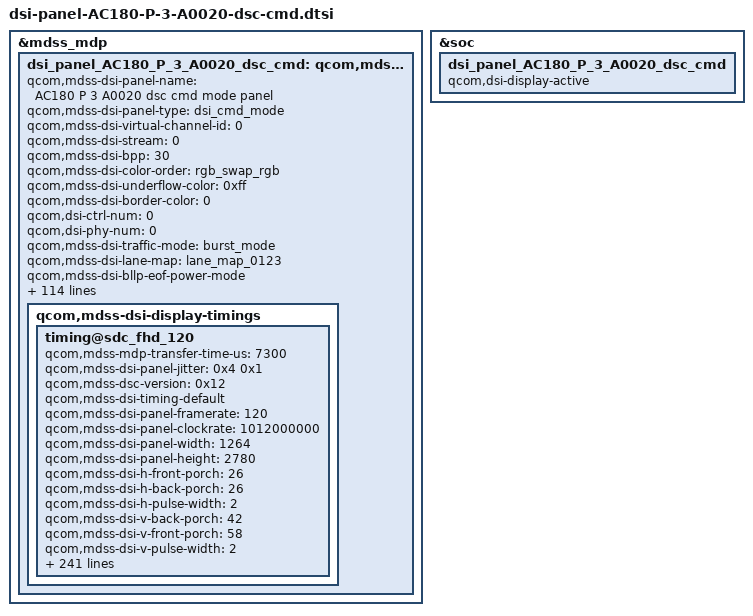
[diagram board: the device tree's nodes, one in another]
&mdss_mdp {
	dsi_panel_AC180_P_3_A0020_dsc_cmd: qcom,mdss_dsi_panel_AC180_P_3_A0020_dsc_cmd {
		qcom,mdss-dsi-panel-name = "AC180 P 3 A0020 dsc cmd mode panel";
		qcom,mdss-dsi-panel-type = "dsi_cmd_mode";
		qcom,mdss-dsi-virtual-channel-id = <0>;
		qcom,mdss-dsi-stream = <0>;
		qcom,mdss-dsi-bpp = <30>;
		qcom,mdss-dsi-color-order = "rgb_swap_rgb";
		qcom,mdss-dsi-underflow-color = <0xff>;
		qcom,mdss-dsi-border-color = <0>;
		qcom,dsi-ctrl-num = <0>;
		qcom,dsi-phy-num = <0>;
		qcom,mdss-dsi-traffic-mode = "burst_mode";
		qcom,mdss-dsi-lane-map = "lane_map_0123";
		qcom,mdss-dsi-bllp-eof-power-mode;
		qcom,mdss-dsi-bllp-power-mode;
		qcom,mdss-dsi-lane-0-state;
		qcom,mdss-dsi-lane-1-state;
		qcom,mdss-dsi-lane-2-state;
		qcom,mdss-dsi-lane-3-state;
		qcom,mdss-dsi-dma-trigger = "trigger_sw";
		qcom,mdss-dsi-dma-schedule-line = <1>;
		qcom,mdss-dsi-dma-schedule-window = <10>;
		qcom,mdss-dsi-mdp-trigger = "none";
		qcom,mdss-dsi-reset-sequence = <1 2>, <0 5>, <1 25>;
		qcom,mdss-dsi-te-pin-select = <1>;
		qcom,mdss-dsi-te-dcs-command = <1>;
		qcom,mdss-pan-physical-width-dimension = <71>;
		qcom,mdss-pan-physical-height-dimension = <157>;
		qcom,mdss-dsi-init-delay-us = <1000>;
		qcom,mdss-dsi-te-check-enable;
		qcom,mdss-dsi-te-using-te-pin;
		qcom,mdss-dsi-lp11-init;
		qcom,mdss-dsi-wr-mem-start = <0x2c>;
		qcom,mdss-dsi-wr-mem-continue = <0x3c>;
		qcom,mdss-dsi-panel-jitter = <0x4 0x1>;
		qcom,mdss-bl-high2bit;
  		/* HDR Setting */
		qcom,mdss-dsi-panel-hdr-enabled;
		qcom,mdss-dsi-panel-hdr-color-primaries = <15635 16450 34000 16000 13250 34500 7500 3000>;
		//update for [MPC15]android.mediapc.cts.PerformanceClassTest#testDisplayHdr pass
		//qcom,mdss-dsi-panel-peak-brightness = <5400000>;
		qcom,mdss-dsi-panel-peak-brightness = <20000000>;
		qcom,mdss-dsi-panel-average-brightness = <2000000>;
		qcom,mdss-dsi-panel-blackness-level = <4000>;


		qcom,dynamic-mode-switch-enabled;
		qcom,dynamic-mode-switch-type = "dynamic-resolution-switch-immediate";
		qcom,mdss-dsi-display-timings {
			timing@sdc_fhd_120 {
				#include "dsi-panel-AC180-P-3-A0020-common.dtsi"
				qcom,mdss-mdp-transfer-time-us = <7300>;
				qcom,mdss-dsi-panel-jitter = <0x4 0x1>;
				qcom,mdss-dsc-version = <0x12>;
				qcom,mdss-dsi-timing-default;
				qcom,mdss-dsi-panel-framerate = <120>;
				qcom,mdss-dsi-panel-clockrate = <1012000000>;
				qcom,mdss-dsi-panel-width = <1264>;
				qcom,mdss-dsi-panel-height = <2780>;

				qcom,mdss-dsi-h-front-porch = <26>;
				qcom,mdss-dsi-h-back-porch = <26>;
				qcom,mdss-dsi-h-pulse-width = <2>;
				qcom,mdss-dsi-v-back-porch = <42>;
				qcom,mdss-dsi-v-front-porch = <58>;
				qcom,mdss-dsi-v-pulse-width = <2>;
				qcom,mdss-dsi-h-sync-pulse = <0>;

				oplus,ofp-need-to-sync-data-in-aod-unlocking;
				oplus,ofp-aod-off-insert-black-frame = <1>;
				oplus,ofp-aod-off-black-frame-total-time = <42>;
				oplus,ofp-need-to-separate-backlight;
				oplus,ofp-backlight-on-period = <1>;

				qcom,mdss-dsi-timing-switch-command = [
					39 00 00 40 00 00 04 FF 5A A5 00
					15 00 00 40 00 00 02 60 00
					/* recover to narrow TE */
					39 00 00 40 00 00 04 FF 5A A5 02
					39 00 00 40 00 00 09 B0 00 80 00 10 00 00 00 00
					39 00 00 40 00 00 04 FF 5A A5 2D
					39 00 00 40 00 00 03 83 00 00
					15 00 00 40 00 00 02 F2 00
					39 00 00 00 00 00 04 FF 5A A5 00
				];
				qcom,mdss-dsi-on-command = [
					39 00 00 40 00 00 04 FF 5A A5 20
					15 00 00 40 00 00 02 BF 06
					39 00 00 40 00 00 04 FF 5A A5 00
					39 00 00 40 00 00 05 94 00 D0 00 00
					39 00 00 40 00 00 04 FF 5A A5 1F
					39 00 00 40 00 00 03 82 00 20
					15 00 00 40 00 00 02 87 09
					15 00 00 40 00 00 02 88 34
					39 00 00 40 00 00 05 89 C1 80 C0 01
					39 00 00 40 00 00 03 8A 8C 14
					39 00 00 40 00 00 05 8C 80 07 00 40
					15 00 00 40 00 00 02 8E 10
					39 00 00 40 00 00 05 96 15 35 55 00
					39 00 00 40 00 00 06 97 11 33 22 01 09
					39 00 00 40 00 00 19 83 00 0B 0A 0C 02 FF FF FF 0C 02 FF FF 00 FF 00 0B 00 FF FF FF FF FF FF FF
					39 00 00 40 00 00 19 8F 03 2D 8C 19 07 00 00 00 19 07 00 00 00 00 02 2D 02 00 00 00 00 00 00 00
					39 00 00 40 00 00 04 85 00 0B 0A
					39 00 00 40 00 00 04 91 03 2D 72
					39 00 00 40 00 00 04 FF 5A A5 29
					39 00 00 40 00 00 09 82 90 90 6C 28 14 14 14 14
					39 00 00 40 00 00 09 83 14 14 14 14 14 14 14 14
					39 00 00 40 00 00 09 84 14 14 14 14 14 14 14 14
					39 00 00 40 00 00 07 85 14 14 14 14 14 14
					39 00 00 40 00 00 04 FF 5A A5 00

					39 00 00 40 00 00 04 FF 5A A5 08
					15 00 00 40 00 00 02 C8 62
					39 00 00 40 00 00 04 FF 5A A5 07
					15 00 00 40 00 00 02 8A 01
					39 00 00 40 00 00 03 8B 21 E0
					39 00 00 40 00 00 64 81 00 00 00 00 00 12 00 00 AB 30 80 0A DC 04 F0 00 14 02 78 02 78 02 00 02 57 00 20 01 F8 00 08 00 0D 05 7A 04 4F 18 00 10 E0 07 10 20 00 06 0F 0F 33 0E 1C 2A 38 46 54 62 69 70 77 79 7B 7D 7E 02 02 22 00 2A 40 2A BE 3A FC 3A FA 3A F8 3B 38 3B 78 3B B6 4B B6 4B F4 4B F4 6C 34 84 74 74 00 00 00 00 00

					39 00 00 40 00 00 04 FF 5A A5 21
					15 00 00 40 00 00 02 A4 18
					39 00 00 40 00 00 04 FF 5A A5 00
					15 00 00 40 00 00 02 5E 01
					15 00 00 40 00 00 02 60 00
					15 00 00 40 00 00 02 61 07
					15 00 00 40 00 00 02 35 00
					15 00 00 40 00 00 02 53 20
					/* decreasing step */
					39 00 00 40 00 00 04 FF 5A A5 2D
					15 00 00 40 00 00 02 97 03
					15 00 00 40 00 00 02 B1 03
					39 00 00 40 00 00 03 98 03 00
					39 00 00 40 00 00 03 99 05 00
					39 00 00 40 00 00 03 9A 0B 00
					39 00 00 40 00 00 03 9B 17 00
					39 00 00 40 00 00 03 A0 00 00
					39 00 00 40 00 00 03 A1 01 02
					15 00 00 40 00 00 03 B2 02 00
					15 00 00 40 00 00 03 B3 04 00
					15 00 00 40 00 00 03 B4 08 00
					15 00 00 40 00 00 03 B5 11 00
					39 00 00 40 00 00 03 BA 00 00
					39 00 00 40 00 00 03 BB 01 02
					/* Narrow TE */
					39 00 00 40 00 00 04 FF 5A A5 02
					39 00 00 40 00 00 09 B0 00 80 00 10 00 00 00 00
					// switch 120HZ
					39 00 00 40 00 00 04 FF 5A A5 00
					15 00 00 40 00 00 02 60 00
					39 00 00 40 00 00 04 FF 5A A5 2D
					39 00 00 40 00 00 03 83 00 00
					15 00 00 40 00 00 02 F2 00
					39 00 00 00 02 00 04 FF 5A A5 00
					//screen on code
					15 00 00 00 78 00 02 11 00
					15 00 00 00 14 00 02 29 00
				];
				qcom,mdss-dsi-off-command=[
					05 00 00 00 14 00 01 28
					05 00 00 00 78 00 01 10
				];
				qcom,mdss-dsi-hbm-off-command = [
					39 00 00 00 00 00 03 51 0D BB
				];
				qcom,mdss-dsi-hbm-on-command = [
					39 00 00 00 00 00 03 51 0E E0
				];
				qcom,mdss-dsi-change-voltage-before-bl-0-command = [
					//Vinit2 ELVSS
					39 00 00 40 00 00 04 FF 5A A5 1F
					15 00 00 40 00 00 02 88 00
					39 00 00 40 00 00 04 FF 5A A5 4E
					15 00 00 40 00 00 02 8C 10
					39 00 00 40 00 00 08 95 00 00 00 00 FF 03 30
					39 00 00 00 00 00 04 FF 5A A5 00
				];
				qcom,mdss-dsi-lhbm-pressed-icon-on-command = [
					39 00 00 40 00 00 04 FF 5A A5 00
					39 00 00 40 00 00 02 96 09
					39 00 00 40 00 00 02 97 D9
					39 00 00 40 00 00 02 98 02
					39 00 00 40 00 00 02 99 78
					39 00 00 00 00 00 02 6E 03
				];
				qcom,mdss-dsi-lhbm-pressed-icon-off-command = [
					39 00 00 40 00 00 04 FF 5A A5 00
					39 00 00 00 00 00 02 6E 00
				];
				qcom,mdss-dsi-lp1-command = [
					39 00 00 40 00 00 04 FF 5A A5 02
					39 00 00 40 00 00 03 88 08 00
					39 00 00 40 00 00 04 FF 5A A5 4F
					15 00 00 40 00 00 02 88 78
					39 00 00 40 00 00 04 FF 5A A5 00
					15 00 00 40 00 00 02 60 00
					39 00 00 40 00 00 04 FF 5A A5 53
					39 00 00 40 00 00 03 85 CC E1
					39 00 00 40 00 00 04 FF 5A A5 01
					39 00 00 40 00 00 06 83 00 00 40 04 00
					15 00 00 40 00 00 02 FE 0B
					39 00 00 40 00 00 04 FF 5A A5 0B
					15 00 00 40 00 00 02 88 00
					15 00 00 40 00 00 02 A7 00
					39 00 00 40 00 00 04 FF 5A A5 51
					39 00 00 40 00 00 06 C2 46 46 46 46 00
					15 00 00 40 00 00 02 FE 00
					15 00 00 40 00 00 02 00 00
					39 00 00 40 00 00 04 FF 5A A5 00
					15 00 00 40 00 00 02 39 00
					39 00 00 40 00 00 04 FF 5A A5 4F
					15 00 00 40 00 00 02 8B 78
					/* AOD lv switch */
					39 00 00 40 00 00 04 FF 5A A5 00
					39 00 00 00 00 00 05 51 00 00 0D BB
				];
				qcom,mdss-dsi-nolp-command = [
					39 00 00 40 00 00 04 FF 5A A5 02
					39 00 00 40 00 00 03 88 C0 00
					39 00 00 40 00 00 04 FF 5A A5 00
					15 00 00 40 00 00 02 38 00
					39 00 00 00 00 00 05 51 00 00 00 00
				];
				qcom,mdss-dsi-aod-off-pwm-mode2-command = [
					39 00 00 40 00 00 04 FF 5A A5 4F
					15 00 00 40 00 00 02 88 78
					39 00 00 40 00 00 04 FF 5A A5 01
					39 00 00 40 00 00 03 80 0C 0C
					39 00 00 40 00 00 04 FF 5A A5 4F
					15 00 00 40 00 00 02 8A 78
					39 00 00 40 00 00 04 FF 5A A5 00
					15 00 00 40 00 00 02 60 01
					39 00 00 40 00 00 04 FF 5A A5 53
					39 00 00 40 00 00 03 85 CC E3
					39 00 00 40 00 00 04 FF 5A A5 01
					39 00 00 40 00 00 06 83 00 00 40 04 00
					15 00 00 40 00 00 02 FE 07
					39 00 00 40 00 00 04 FF 5A A5 0B
					15 00 00 40 00 00 02 88 46
					15 00 00 40 00 00 02 A7 3A
					39 00 00 40 00 00 04 FF 5A A5 51
					39 00 00 40 00 00 06 C2 46 28 28 28 00
					15 00 00 40 00 00 02 FE 00
					15 00 00 40 00 00 02 00 00
					39 00 00 40 00 00 04 FF 5A A5 01
					39 00 00 40 00 00 03 80 0C 00
					39 00 00 40 00 00 04 FF 5A A5 02
					39 00 00 40 00 00 03 88 C0 00
					39 00 00 40 00 00 04 FF 5A A5 00
					15 00 00 40 00 00 02 38 00
					39 00 00 40 00 00 04 FF 5A A5 4F
					15 00 00 40 00 00 02 8B 78
					39 00 00 40 00 00 04 FF 5A A5 00
					39 00 00 00 00 00 03 51 00 00
				];
				qcom,mdss-dsi-aod-off-compensation-command = [
					39 00 00 40 00 00 04 FF 5A A5 02
					39 00 00 40 00 00 03 88 C0 00
					39 00 00 40 00 00 04 FF 5A A5 4F
					15 00 00 40 00 00 02 80 01
					15 00 00 40 00 00 02 81 04
					15 00 00 40 00 00 02 88 78
					39 00 00 40 00 00 04 FF 5A A5 1F
					39 00 00 40 00 00 06 89 43 00 0B F0 BB
					39 00 00 40 00 00 03 82 08 08
					39 00 00 40 00 00 06 85 7F 7F 7F 7F 73
					39 00 00 40 00 00 04 FF 5A A5 00
					15 00 00 40 00 00 02 4D 01
					39 00 00 40 00 00 04 FF 5A A5 13
					15 00 00 40 00 00 02 CB 00
					39 00 00 40 00 00 04 FF 5A A5 4F
					15 00 00 40 00 00 02 8A 78
					39 00 00 40 00 00 04 FF 5A A5 1F
					39 00 00 40 00 00 06 89 43 00 04 F0 55
					39 00 00 40 00 00 03 82 00 80
					39 00 00 40 00 00 06 85 5F 7F 00 00 00
					39 00 00 40 00 00 04 FF 5A A5 00
					15 00 00 40 00 00 02 38 00
					39 00 00 40 00 00 04 FF 5A A5 00
					15 00 00 40 00 00 02 4D 00
					39 00 00 40 00 00 04 FF 5A A5 13
					15 00 00 40 00 00 02 CB 01
					39 00 00 40 00 00 04 FF 5A A5 00
					15 00 00 40 00 00 02 00 00
					39 00 00 40 00 00 04 FF 5A A5 4F
					15 00 00 00 00 00 02 8B 78
				];
				qcom,mdss-dsi-aod-off-compensation-onepulse-command = [
					39 00 00 40 00 00 04 FF 5A A5 02
					39 00 00 40 00 00 03 88 C0 00
					39 00 00 40 00 00 04 FF 5A A5 4F
					15 00 00 40 00 00 02 80 01
					15 00 00 40 00 00 02 81 04
					15 00 00 40 00 00 02 88 78
					39 00 00 40 00 00 04 FF 5A A5 01
					39 00 00 40 00 00 03 80 0C 0C
					39 00 00 40 00 00 04 FF 5A A5 1F
					39 00 00 40 00 00 06 89 43 00 0B F0 BB
					39 00 00 40 00 00 03 82 08 08
					39 00 00 40 00 00 06 85 7F 7F 7F 7F 73
					39 00 00 40 00 00 04 FF 5A A5 00
					15 00 00 40 00 00 02 4D 01
					39 00 00 40 00 00 04 FF 5A A5 13
					15 00 00 40 00 00 02 CB 00
					39 00 00 40 00 00 04 FF 5A A5 4F
					15 00 00 40 00 00 02 8A 78
					39 00 00 40 00 00 04 FF 5A A5 1F
					39 00 00 40 00 00 06 89 43 00 04 F0 55
					39 00 00 40 00 00 03 82 00 80
					39 00 00 40 00 00 06 85 5F 7F 00 00 00
					39 00 00 40 00 00 04 FF 5A A5 00
					15 00 00 40 00 00 02 60 01
					39 00 00 40 00 00 04 FF 5A A5 53
					39 00 00 40 00 00 03 85 CC E3
					39 00 00 40 00 00 04 FF 5A A5 01
					39 00 00 40 00 00 06 83 00 00 40 04 00
					15 00 00 40 00 00 02 FE 07
					39 00 00 40 00 00 04 FF 5A A5 0B
					15 00 00 40 00 00 02 88 46
					15 00 00 40 00 00 02 A7 3A
					39 00 00 40 00 00 04 FF 5A A5 51
					39 00 00 40 00 00 06 C2 46 28 28 28 00
					15 00 00 40 00 00 02 FE 00
					15 00 00 40 00 00 02 00 00
					39 00 00 40 00 00 04 FF 5A A5 01
					39 00 00 40 00 00 03 80 0C 00
					39 00 00 40 00 00 04 FF 5A A5 00
					15 00 00 40 00 00 02 38 00
					39 00 00 40 00 00 04 FF 5A A5 00
					15 00 00 40 00 00 02 4D 00
					39 00 00 40 00 00 04 FF 5A A5 13
					15 00 00 40 00 00 02 CB 01
					39 00 00 40 00 00 04 FF 5A A5 00
					15 00 00 40 00 00 02 00 00
					39 00 00 40 00 00 04 FF 5A A5 4F
					15 00 00 00 00 00 02 8B 78
				];
				qcom,mdss-dsi-aod-high-mode-command = [
					39 00 00 40 00 00 04 FF 5A A5 00
					39 00 00 00 00 00 05 51 00 00 0D BB
				];
				qcom,mdss-dsi-aod-low-mode-command = [
					39 00 00 40 00 00 04 FF 5A A5 00
					39 00 00 00 00 00 05 51 00 00 0A 81
				];
				qcom,mdss-dsi-ultra-low-power-aod-on-command = [
					39 00 00 40 00 00 04 FF 5A A5 2D
					39 00 00 40 00 00 03 8A 1D 00
					39 00 00 00 00 00 04 FF 5A A5 00
				];
				qcom,mdss-dsi-ultra-low-power-aod-off-command = [
					39 00 00 40 00 00 04 FF 5A A5 2D
					39 00 00 40 00 00 03 8A 00 00
					39 00 00 00 00 00 04 FF 5A A5 00
				];
				/* pwm */
				qcom,mdss-dsi-pwm-state-l3tol2-command = [
					39 00 00 40 00 00 04 FF 5A A5 08
					15 00 00 40 00 00 02 98 02
					39 00 00 40 00 00 04 FF 5A A5 4F
					15 00 00 40 00 00 02 81 06
					15 00 00 40 00 00 02 80 01
					15 00 00 40 00 00 02 88 78
					39 00 00 40 00 00 04 FF 5A A5 00
					39 00 00 40 00 00 03 51 04 8B
					39 00 00 40 00 00 04 FF 5A A5 24
					39 00 00 40 00 00 06 C9 00 00 00 10 00
					39 00 00 40 00 00 04 FE 30 00 50
					39 00 00 40 00 00 06 CA 00 80 00 A0 00
					39 00 00 40 00 00 04 FE C0 00 D8
					39 00 00 40 00 00 06 CB 01 10 01 78 01
					39 00 00 40 00 00 04 FE B0 02 98
					39 00 00 40 00 00 06 CC 03 20 04 40 05
					39 00 00 40 00 00 04 FE 20 05 E8
					39 00 00 40 00 00 06 CD 06 F0 07 C8 09
					39 00 00 40 00 00 04 FE 30 0A A8
					39 00 00 40 00 00 06 CE 0B 70 0C D8 0E
					39 00 00 40 00 00 04 FE F0 0F F0
					39 00 00 40 00 00 04 FF 5A A5 4F
					15 00 00 40 00 00 02 8A 78
					39 00 00 40 00 00 04 FF 5A A5 24
					39 00 00 40 00 00 06 C9 00 00 00 10 00
					39 00 00 40 00 00 04 FE 30 00 50
					39 00 00 40 00 00 06 CA 00 80 00 B0 00
					39 00 00 40 00 00 04 FE D0 01 10
					39 00 00 40 00 00 06 CB 01 50 01 B0 02
					39 00 00 40 00 00 04 FE 10 02 B0
					39 00 00 40 00 00 06 CC 03 70 04 70 05
					39 00 00 40 00 00 04 FE 70 06 30
					39 00 00 40 00 00 06 CD 07 10 08 10 09
					39 00 00 40 00 00 04 FE 80 0A F0
					39 00 00 40 00 00 06 CE 0B A0 0D 10 0E
					39 00 00 40 00 00 04 FE F0 0F F0
					39 00 00 40 00 00 04 FF 5A A5 08
					15 00 00 40 00 00 02 98 A6
					39 00 00 40 00 00 04 FF 5A A5 00
					15 00 00 40 00 00 02 00 00
					39 00 00 40 00 00 04 FF 5A A5 4F
					15 00 00 00 00 00 02 8B 78
				];
				qcom,mdss-dsi-pwm-state-l2tol3-command = [
					39 00 00 40 00 00 04 FF 5A A5 08
					15 00 00 40 00 00 02 98 02
					39 00 00 40 00 00 04 FF 5A A5 4F
					15 00 00 40 00 00 02 81 06
					15 00 00 40 00 00 02 80 01
					15 00 00 40 00 00 02 88 78
					39 00 00 40 00 00 04 FF 5A A5 00
					39 00 00 40 00 00 03 51 04 8A
					39 00 00 40 00 00 04 FF 5A A5 24
					39 00 00 40 00 00 06 C9 00 00 00 10 00
					39 00 00 40 00 00 04 FE 30 00 50
					39 00 00 40 00 00 06 CA 00 80 00 B0 00
					39 00 00 40 00 00 04 FE D0 01 34
					39 00 00 40 00 00 06 CB 01 78 01 B8 02
					39 00 00 40 00 00 04 FE 48 02 F8
					39 00 00 40 00 00 06 CC 03 70 04 A0 05
					39 00 00 40 00 00 04 FE B0 06 78
					39 00 00 40 00 00 06 CD 07 30 08 50 09
					39 00 00 40 00 00 04 FE E0 0B 44
					39 00 00 40 00 00 06 CE 0B D8 0D 10 0E
					39 00 00 40 00 00 04 FE F0 0F F0
					39 00 00 40 00 00 04 FF 5A A5 4F
					15 00 00 40 00 00 02 8A 78
					39 00 00 40 00 00 04 FF 5A A5 24
					39 00 00 40 00 00 06 C9 00 00 00 10 00
					39 00 00 40 00 00 04 FE 30 00 50
					39 00 00 40 00 00 06 CA 00 80 00 B0 00
					39 00 00 40 00 00 04 FE D0 01 10
					39 00 00 40 00 00 06 CB 01 50 01 B0 02
					39 00 00 40 00 00 04 FE 10 02 B0
					39 00 00 40 00 00 06 CC 03 70 04 70 05
					39 00 00 40 00 00 04 FE 70 06 30
					39 00 00 40 00 00 06 CD 07 10 08 10 09
					39 00 00 40 00 00 04 FE 80 0A F0
					39 00 00 40 00 00 06 CE 0B A0 0D 10 0E
					39 00 00 40 00 00 04 FE F0 0F F0
					39 00 00 40 00 00 04 FF 5A A5 08
					15 00 00 40 00 00 02 98 A6
					39 00 00 40 00 00 04 FF 5A A5 00
					15 00 00 40 00 00 02 00 00
					39 00 00 40 00 00 04 FF 5A A5 4F
					15 00 00 00 00 00 02 8B 78
				];
				qcom,mdss-dsi-pwm-switch-mode0-command= [
					39 00 00 40 00 00 04 FF 5A A5 08
					15 00 00 40 00 00 02 98 02
					39 00 00 40 00 00 04 FF 5A A5 4F
					15 00 00 40 00 00 02 81 06
					15 00 00 40 00 00 02 88 78
					39 00 00 40 00 00 04 FF 5A A5 01
					39 00 00 40 00 00 06 83 00 00 40 04 00
					15 00 00 40 00 00 02 FE 0B
					39 00 00 40 00 00 04 FF 5A A5 0B
					15 00 00 40 00 00 02 88 00
					15 00 00 40 00 00 02 A7 00
					39 00 00 40 00 00 04 FF 5A A5 51
					39 00 00 40 00 00 06 C2 46 46 46 46 00
					15 00 00 40 00 00 02 FE 00
					15 00 00 40 00 00 02 00 00
					39 00 00 40 00 00 06 A0 98 98 A4 A8 22
					15 00 00 40 00 00 02 FE 22
					15 00 00 40 00 00 02 00 00
					39 00 00 40 00 00 06 A1 CC D0 D0 A2 22
					15 00 00 40 00 00 02 FE 22
					15 00 00 40 00 00 02 00 00
					39 00 00 40 00 00 06 A2 A4 A6 99 9A 22
					15 00 00 40 00 00 02 FE 22
					15 00 00 40 00 00 02 00 00
					39 00 00 40 00 00 04 FF 5A A5 52
					39 00 00 40 00 00 06 80 DA DA 58 B1 11
					15 00 00 40 00 00 02 FE 01
					15 00 00 40 00 00 02 00 00
					39 00 00 40 00 00 06 81 4D 4D 4D 4E 00
					15 00 00 40 00 00 02 FE 00
					15 00 00 40 00 00 02 00 00
					39 00 00 40 00 00 06 82 4D 4E 4D 4D 00
					15 00 00 40 00 00 02 FE 00
					15 00 00 40 00 00 02 00 00
					39 00 00 40 00 00 04 FF 5A A5 00
					15 00 00 40 00 00 02 60 00
					39 00 00 40 00 00 04 FF 5A A5 08
					15 00 00 40 00 00 02 98 A6
					39 00 00 40 00 00 04 FF 5A A5 00
					15 00 00 40 00 00 02 00 00
					39 00 00 40 00 00 04 FF 5A A5 4F
					15 00 00 40 00 00 02 8B 78
					39 00 00 40 00 00 04 FF 5A A5 53
					15 00 00 40 00 00 02 F0 01
					39 00 00 40 00 00 04 FF 5A A5 63
					39 00 00 40 00 00 11 F1 00 00 00 00 00 00 00 00 00 00 00 00 00 00 00 00
					39 00 00 40 00 00 11 F2 10 10 10 10 10 00 00 00 00 00 00 00 00 00 00 00
					39 00 00 40 00 00 11 F3 00 00 00 00 00 20 20 20 20 20 00 00 00 00 00 00
					39 00 00 40 00 00 11 F4 00 00 00 00 00 F0 F0 F0 F0 F0 00 00 00 00 00 00
					39 00 00 40 00 00 04 FF 5A A5 53
					15 00 00 40 00 00 02 F0 00
					39 00 00 00 00 00 04 FF 5A A5 00
				];
				qcom,mdss-dsi-pwm-switch-mode2-command = [
					39 00 00 40 00 00 04 FF 5A A5 08
					15 00 00 40 00 00 02 98 02
					39 00 00 40 00 00 04 FF 5A A5 4F
					15 00 00 40 00 00 02 81 06
					15 00 00 40 00 00 02 88 78
					39 00 00 40 00 00 04 FF 5A A5 51
					39 00 00 40 00 00 06 C2 46 28 28 28 00
					15 00 00 40 00 00 02 FE 00
					15 00 00 40 00 00 02 00 00
					39 00 00 40 00 00 06 A0 98 98 6C 69 22
					15 00 00 40 00 00 02 FE 22
					15 00 00 40 00 00 02 00 00
					39 00 00 40 00 00 06 A1 8C 91 91 74 22
					15 00 00 40 00 00 02 FE 22
					15 00 00 40 00 00 02 00 00
					39 00 00 40 00 00 06 A2 68 72 72 72 22
					15 00 00 40 00 00 02 FE 22
					15 00 00 40 00 00 02 00 00
					39 00 00 40 00 00 04 FF 5A A5 52
					39 00 00 40 00 00 06 80 DA DA 49 A5 11
					15 00 00 40 00 00 02 FE 01
					15 00 00 40 00 00 02 00 00
					39 00 00 40 00 00 06 81 3D 3E 3E 3F 00
					15 00 00 40 00 00 02 FE 00
					15 00 00 40 00 00 02 00 00
					39 00 00 40 00 00 06 82 41 23 23 23 00
					15 00 00 40 00 00 02 FE 00
					15 00 00 40 00 00 02 00 00
					39 00 00 40 00 00 04 FF 5A A5 00
					15 00 00 40 00 00 02 60 01
					39 00 00 40 00 00 04 FF 5A A5 4F
					15 00 00 40 00 00 02 8A 78
					39 00 00 40 00 00 04 FF 5A A5 01
					39 00 00 40 00 00 06 83 00 00 40 04 00
					15 00 00 40 00 00 02 FE 07
					39 00 00 40 00 00 04 FF 5A A5 0B
					15 00 00 40 00 00 02 88 46
					15 00 00 40 00 00 02 A7 3A
					39 00 00 40 00 00 04 FF 5A A5 08
					15 00 00 40 00 00 02 98 A6
					39 00 00 40 00 00 04 FF 5A A5 00
					15 00 00 40 00 00 02 00 00
					39 00 00 40 00 00 04 FF 5A A5 4F
					15 00 00 40 00 00 02 8B 78
					39 00 00 40 00 00 04 FF 5A A5 53
					15 00 00 40 00 00 02 F0 01
					39 00 00 40 00 00 04 FF 5A A5 63
					39 00 00 40 00 00 11 F1 20 20 20 20 20 20 20 20 20 20 00 00 00 00 00 00
					39 00 00 40 00 00 11 F2 00 00 00 00 00 00 00 00 00 00 00 00 00 00 00 00
					39 00 00 40 00 00 11 F3 00 00 00 00 00 00 00 00 00 00 00 00 00 00 00 00
					39 00 00 40 00 00 11 F4 F0 F0 F0 F0 F0 F0 F0 F0 F0 F0 00 00 00 00 00 00
					39 00 00 40 00 00 04 FF 5A A5 53
					15 00 00 40 00 00 02 F0 00
					39 00 00 00 00 00 04 FF 5A A5 00
				];
				qcom,mdss-dsi-timming-switch-pwm-mode2-command = [
					39 00 00 40 00 00 04 FF 5A A5 00
					15 00 00 40 00 00 02 60 01
					39 00 00 40 00 00 04 FF 5A A5 2D
					39 00 00 40 00 00 03 84 00 00
					15 00 00 40 00 00 02 F2 00
					39 00 00 00 00 00 04 FF 5A A5 00
				];
				qcom,mdss-dsi-pwm-switch-mode2-panel-on-command = [
					39 00 00 40 00 00 04 FF 5A A5 08
					15 00 00 40 00 00 02 98 02
					39 00 00 40 00 00 04 FF 5A A5 4F
					15 00 00 40 00 00 02 81 06
					15 00 00 40 00 00 02 88 78
					39 00 00 40 00 00 04 FF 5A A5 51
					39 00 00 40 00 00 06 C2 46 28 28 28 00
					15 00 00 40 00 00 02 FE 00
					15 00 00 40 00 00 02 00 00
					39 00 00 40 00 00 06 A0 98 98 6C 69 22
					15 00 00 40 00 00 02 FE 22
					15 00 00 40 00 00 02 00 00
					39 00 00 40 00 00 06 A1 8C 91 91 74 22
					15 00 00 40 00 00 02 FE 22
					15 00 00 40 00 00 02 00 00
					39 00 00 40 00 00 06 A2 68 72 72 72 22
					15 00 00 40 00 00 02 FE 22
					15 00 00 40 00 00 02 00 00
					39 00 00 40 00 00 04 FF 5A A5 52
					39 00 00 40 00 00 06 80 DA DA 49 A5 11
					15 00 00 40 00 00 02 FE 01
					15 00 00 40 00 00 02 00 00
					39 00 00 40 00 00 06 81 3D 3E 3E 3F 00
					15 00 00 40 00 00 02 FE 00
					15 00 00 40 00 00 02 00 00
					39 00 00 40 00 00 06 82 41 23 23 23 00
					15 00 00 40 00 00 02 FE 00
					15 00 00 40 00 00 02 00 00
					39 00 00 40 00 00 04 FF 5A A5 00
					15 00 00 40 00 00 02 60 01
					39 00 00 40 00 00 04 FF 5A A5 4F
					15 00 00 40 00 00 02 8A 78
					39 00 00 40 00 00 04 FF 5A A5 01
					39 00 00 40 00 00 06 83 00 00 40 04 00
					15 00 00 40 00 00 02 FE 07
					39 00 00 40 00 00 04 FF 5A A5 0B
					15 00 00 40 00 00 02 88 46
					15 00 00 40 00 00 02 A7 3A
					39 00 00 40 00 00 04 FF 5A A5 08
					15 00 00 40 00 00 02 98 A6
					39 00 00 40 00 00 04 FF 5A A5 00
					15 00 00 40 00 00 02 00 00
					39 00 00 40 00 00 04 FF 5A A5 4F
					15 00 00 40 00 00 02 8B 78
					39 00 00 40 00 00 04 FF 5A A5 53
					15 00 00 40 00 00 02 F0 01
					39 00 00 40 00 00 04 FF 5A A5 63
					39 00 00 40 00 00 11 F1 20 20 20 20 20 20 20 20 20 20 00 00 00 00 00 00
					39 00 00 40 00 00 11 F2 00 00 00 00 00 00 00 00 00 00 00 00 00 00 00 00
					39 00 00 40 00 00 11 F3 00 00 00 00 00 00 00 00 00 00 00 00 00 00 00 00
					39 00 00 40 00 00 11 F4 F0 F0 F0 F0 F0 F0 F0 F0 F0 F0 00 00 00 00 00 00
					39 00 00 40 00 00 04 FF 5A A5 53
					15 00 00 40 00 00 02 F0 00
					39 00 00 00 10 00 04 FF 5A A5 00
				];
				qcom,mdss-dsi-pwm-state-l1tol3-command = [
					39 00 00 40 00 00 04 FF 5A A5 08
					15 00 00 40 00 00 02 98 02
					39 00 00 40 00 00 04 FF 5A A5 4F
					15 00 00 40 00 00 02 81 06
					15 00 00 40 00 00 02 88 78
					39 00 00 40 00 00 04 FF 5A A5 01
					39 00 00 40 00 00 06 83 00 00 40 04 00
					15 00 00 40 00 00 02 FE 0B
					39 00 00 40 00 00 04 FF 5A A5 0B
					15 00 00 40 00 00 02 88 00
					15 00 00 40 00 00 02 A7 00
					39 00 00 40 00 00 04 FF 5A A5 51
					39 00 00 40 00 00 06 C2 46 46 46 46 00
					15 00 00 40 00 00 02 FE 00
					15 00 00 40 00 00 02 00 00
					39 00 00 40 00 00 06 A0 98 98 A4 A8 22
					15 00 00 40 00 00 02 FE 22
					15 00 00 40 00 00 02 00 00
					39 00 00 40 00 00 06 A1 CC D0 D0 A2 22
					15 00 00 40 00 00 02 FE 22
					15 00 00 40 00 00 02 00 00
					39 00 00 40 00 00 06 A2 A4 A6 99 9A 22
					15 00 00 40 00 00 02 FE 22
					15 00 00 40 00 00 02 00 00
					39 00 00 40 00 00 04 FF 5A A5 52
					39 00 00 40 00 00 06 80 DA DA 58 B1 11
					15 00 00 40 00 00 02 FE 01
					15 00 00 40 00 00 02 00 00
					39 00 00 40 00 00 06 81 4D 4D 4D 4E 00
					15 00 00 40 00 00 02 FE 00
					15 00 00 40 00 00 02 00 00
					39 00 00 40 00 00 06 82 4D 4E 4D 4D 00
					15 00 00 40 00 00 02 FE 00
					15 00 00 40 00 00 02 00 00
					39 00 00 40 00 00 04 FF 5A A5 00
					15 00 00 40 00 00 02 60 00
					39 00 00 40 00 00 03 51 04 8A
					39 00 00 40 00 00 04 FF 5A A5 08
					15 00 00 40 00 00 02 98 A6
					39 00 00 40 00 00 04 FF 5A A5 00
					15 00 00 40 00 00 02 00 00
					39 00 00 40 00 00 04 FF 5A A5 4F
					15 00 00 40 00 00 02 8B 78
					39 00 00 40 00 00 04 FF 5A A5 53
					15 00 00 40 00 00 02 F0 01
					39 00 00 40 00 00 04 FF 5A A5 63
					39 00 00 40 00 00 11 F1 00 00 00 00 00 00 00 00 00 00 00 00 00 00 00 00
					39 00 00 40 00 00 11 F2 10 10 10 10 10 00 00 00 00 00 00 00 00 00 00 00
					39 00 00 40 00 00 11 F3 00 00 00 00 00 20 20 20 20 20 00 00 00 00 00 00
					39 00 00 40 00 00 11 F4 00 00 00 00 00 F0 F0 F0 F0 F0 00 00 00 00 00 00
					39 00 00 40 00 00 04 FF 5A A5 53
					15 00 00 40 00 00 02 F0 00
					39 00 00 00 00 00 04 FF 5A A5 00
				];
				qcom,mdss-dsi-pwm-state-l3tol1-command = [
					39 00 00 40 00 00 04 FF 5A A5 08
					15 00 00 40 00 00 02 98 02
					39 00 00 40 00 00 04 FF 5A A5 4F
					15 00 00 40 00 00 02 81 06
					15 00 00 40 00 00 02 88 78
					39 00 00 40 00 00 04 FF 5A A5 01
					39 00 00 40 00 00 03 80 0C 0C
					39 00 00 40 00 00 04 FF 5A A5 24
					39 00 00 40 00 00 06 C9 00 00 00 10 00
					39 00 00 40 00 00 04 FE 30 00 50
					39 00 00 40 00 00 06 CA 00 80 00 B0 00
					39 00 00 40 00 00 04 FE E0 01 40
					39 00 00 40 00 00 06 CB 01 70 01 E8 02
					39 00 00 40 00 00 04 FE 28 02 C0
					39 00 00 40 00 00 06 CC 03 80 04 80 05
					39 00 00 40 00 00 04 FE 70 06 30
					39 00 00 40 00 00 06 CD 07 10 08 10 09
					39 00 00 40 00 00 04 FE 68 0A A8
					39 00 00 40 00 00 06 CE 0B 70 0C D8 0E
					39 00 00 40 00 00 04 FE F0 0F F0
					39 00 00 40 00 00 04 FF 5A A5 4F
					15 00 00 40 00 00 02 8A 78
					39 00 00 40 00 00 04 FF 5A A5 24
					39 00 00 40 00 00 06 C9 00 00 00 10 00
					39 00 00 40 00 00 04 FE 30 00 50
					39 00 00 40 00 00 06 CA 00 80 00 B0 00
					39 00 00 40 00 00 04 FE D0 01 10
					39 00 00 40 00 00 06 CB 01 50 01 B0 02
					39 00 00 40 00 00 04 FE 10 02 B0
					39 00 00 40 00 00 06 CC 03 70 04 70 05
					39 00 00 40 00 00 04 FE 70 06 30
					39 00 00 40 00 00 06 CD 07 10 08 10 09
					39 00 00 40 00 00 04 FE 80 0A F0
					39 00 00 40 00 00 06 CE 0B A0 0D 10 0E
					39 00 00 40 00 00 04 FE F0 0F F0
					39 00 00 40 00 00 04 FF 5A A5 01
					39 00 00 40 00 00 06 83 00 00 40 04 00
					15 00 00 40 00 00 02 FE 07
					39 00 00 40 00 00 04 FF 5A A5 0B
					15 00 00 40 00 00 02 88 46
					15 00 00 40 00 00 02 A7 3A
					39 00 00 40 00 00 04 FF 5A A5 51
					39 00 00 40 00 00 06 C2 46 28 28 28 00
					15 00 00 40 00 00 02 FE 00
					15 00 00 40 00 00 02 00 00
					39 00 00 40 00 00 06 A0 98 98 6C 69 22
					15 00 00 40 00 00 02 FE 22
					15 00 00 40 00 00 02 00 00
					39 00 00 40 00 00 06 A1 8C 91 91 74 22
					15 00 00 40 00 00 02 FE 22
					15 00 00 40 00 00 02 00 00
					39 00 00 40 00 00 06 A2 68 72 72 72 22
					15 00 00 40 00 00 02 FE 22
					15 00 00 40 00 00 02 00 00
					39 00 00 40 00 00 04 FF 5A A5 52
					39 00 00 40 00 00 06 80 DA DA 49 A5 11
					15 00 00 40 00 00 02 FE 01
					15 00 00 40 00 00 02 00 00
					39 00 00 40 00 00 06 81 3D 3E 3E 3F 00
					15 00 00 40 00 00 02 FE 00
					15 00 00 40 00 00 02 00 00
					39 00 00 40 00 00 06 82 41 23 23 23 00
					15 00 00 40 00 00 02 FE 00
					15 00 00 40 00 00 02 00 00
					39 00 00 40 00 00 04 FF 5A A5 00
					15 00 00 40 00 00 02 60 01
					39 00 00 40 00 00 03 51 04 8B
					39 00 00 40 00 00 04 FF 5A A5 01
					39 00 00 40 00 00 03 80 0C 00
					39 00 00 40 00 00 04 FF 5A A5 08
					15 00 00 40 00 00 02 98 A6
					39 00 00 40 00 00 04 FF 5A A5 00
					15 00 00 40 00 00 02 00 00
					39 00 00 40 00 00 04 FF 5A A5 4F
					15 00 00 40 00 00 02 8B 78
					39 00 00 40 00 00 04 FF 5A A5 53
					15 00 00 40 00 00 02 F0 01
					39 00 00 40 00 00 04 FF 5A A5 63
					39 00 00 40 00 00 11 F1 20 20 20 20 20 20 20 20 20 20 00 00 00 00 00 00
					39 00 00 40 00 00 11 F2 00 00 00 00 00 00 00 00 00 00 00 00 00 00 00 00
					39 00 00 40 00 00 11 F3 00 00 00 00 00 00 00 00 00 00 00 00 00 00 00 00
					39 00 00 40 00 00 11 F4 F0 F0 F0 F0 F0 F0 F0 F0 F0 F0 00 00 00 00 00 00
					39 00 00 40 00 00 04 FF 5A A5 53
					15 00 00 40 00 00 02 F0 00
					39 00 00 00 00 00 04 FF 5A A5 00
				];
				qcom,mdss-dsi-hbm-max-command = [
					39 00 00 00 00 00 03 51 10 ED
				];
				qcom,mdss-dsi-hbm-exit-max-command = [
					39 00 00 00 00 00 03 51 0F FE
				];
				qcom,mdss-dsi-lp1-command-state = "dsi_hs_mode";
				qcom,mdss-dsi-nolp-command-state = "dsi_hs_mode";
				qcom,mdss-dsi-aod-off-pwm-mode2-command-state = "dsi_hs_mode";
				qcom,mdss-dsi-aod-off-compensation-command-state = "dsi_lp_mode";
				qcom,mdss-dsi-aod-off-compensation-onepulse-command-state = "dsi_lp_mode";
				qcom,mdss-dsi-nolp-hpwm-command-state = "dsi_lp_mode";
				qcom,mdss-dsi-hbm-on-command-state = "dsi_hs_mode";
				qcom,mdss-dsi-hbm-off-command-state = "dsi_hs_mode";
				qcom,mdss-dsi-panel-read-register-open-state = "dsi_lp_mode";
				qcom,mdss-dsi-panel-read-register-close-state = "dsi_lp_mode";
				qcom,mdss-dsi-lhbm-pressed-icon-gamma-command-state = "dsi_lp_mode";
				qcom,mdss-dsi-lhbm-pressed-icon-grayscale-command-state = "dsi_lp_mode";
				qcom,mdss-dsi-lhbm-pressed-icon-on-command-state = "dsi_lp_mode";
				qcom,mdss-dsi-lhbm-pressed-icon-off-command-state = "dsi_lp_mode";
				qcom,mdss-dsi-lhbm-dbv-alpha-command-state = "dsi_hs_mode";

				qcom,mdss-dsi-reset-scanline-command-state = "dsi_hs_mode";
				qcom,mdss-dsi-recovery-scanline-command-state = "dsi_hs_mode";

				qcom,mdss-dsi-osc-track-on-command-state = "dsi_hs_mode";
				qcom,mdss-dsi-osc-track-off-command-state = "dsi_hs_mode";
				qcom,mdss-dsi-hbm-max-command-state = "dsi_hs_mode";
				qcom,mdss-dsi-hbm-exit-max-command-state = "dsi_hs_mode";

				qcom,lm-split = <632 632>;
				qcom,compression-mode = "dsc";
				qcom,mdss-dsc-encoders = <2>;
				qcom,mdss-dsc-slice-height = <20>;
				qcom,mdss-dsc-slice-width = <632>;
				qcom,mdss-dsc-slice-per-pkt = <2>;
				qcom,mdss-dsc-bit-per-component = <10>;
				qcom,mdss-dsc-bit-per-pixel = <8>;
				qcom,mdss-dsc-block-prediction-enable;
			};
		};
	};
};

&soc {
	dsi_panel_AC180_P_3_A0020_dsc_cmd {
		qcom,dsi-display-active;
	};
};

&dsi_panel_AC180_P_3_A0020_dsc_cmd {
	qcom,panel-supply-entries = <&oplus_dsi_panel_custom_pwr_supply>;
	qcom,platform-te-gpio = <&tlmm 86 0>;
	qcom,platform-reset-gpio = <&tlmm 171 0>;
	/* OLED_PMIC_RST */
	oplus,panel-gpio1 = <&pmk8850_gpios 1 0>;
	/* VDDR_SM_1P5_EN */
	oplus,panel-gpio2 = <&pmh0101_gpios 4 0>;

    oplus,panel-reset-position = <0x02>;
	oplus,panel-power-on-sequence = "1", "vddio", "3", "vdd","3", "gpio1", "3", "gpio2", "3", "vci", "10";
	oplus,panel-power-off-sequence = "1", "vci", "3", "gpio2", "3", "gpio1", "3", "vdd", "3", "vddio", "1";

    //enable mipi strength
	oplus,enhance_mipi_strength;

    /* BRIGHTNESS CONFIG */
    qcom,mdss-dsi-bl-pmic-control-type = "bl_ctrl_dcs";
	qcom,bl-update-flag = "delay_until_first_frame";
    qcom,mdss-dsi-bl-inverted-dbv;
    qcom,mdss-dsi-bl-min-level = <1>;
	qcom,mdss-dsi-bl-max-level = <4094>;
	qcom,mdss-brightness-max-level = <4094>;
	oplus,dsi-bl-normal-max-level = <3515>;
	oplus,dsi-brightness-normal-max-level = <3515>;
	oplus,dsi-dc-backlight-threshold = <1960>;
	oplus,dsi-brightness-default-level = <1638>;

    /* ESD CONFIG */
    //qcom,esd-check-enabled;
    oplus,esd-check-flag-enabled;
    qcom,mdss-dsi-panel-status-check-mode = "reg_read";
    qcom,mdss-dsi-panel-status-command = [
            06 00 00 00 00 00 01 0A
        ];
    qcom,mdss-dsi-panel-status-command-state = "dsi_lp_mode";
    qcom,mdss-dsi-panel-status-value = <
            0x9C
    >;
    qcom,mdss-dsi-panel-status-read-length = <1>;
    oplus,mdss-dsi-panel-status-match-modes = <0x00000000>;

    /* FACTORY CONFIG */
    oplus,mdss-dsi-vendor-name = "A0020";
    oplus,mdss-dsi-manufacture = "P_3";
    oplus,color_vivid_status;
	oplus,color_srgb_status;
	oplus,color_softiris_status;
	oplus,color_dual_brightness_status;
	oplus,color_2nit_status;
	oplus,color_oplus_calibrate_status;
	oplus,color_samsung_status;
	oplus,color_loading_status;
	oplus,color_nature_profession_status;
	oplus,mdss-dsi-panel-type = <0>;

    /* OPLUS FEATURES CONFIG */
	oplus,dsi-serial-number-enabled;
	oplus,dsi-serial-number-switch-page;
	oplus,dsi-serial-number-index= <0>;
	oplus,dsi-serial-number-reg= <0x82>;
	oplus,dsi-serial-number-read-count= <7>;
	qcom,ulps-enabled;
	qcom,dsi-select-clocks = "pll_byte_clk0", "pll_dsi_clk0";

	oplus,vreg_ctrl_flag;

	/* ofp config */
	oplus,ofp-fp-type = <0x90>;
	oplus,ofp-longrui-aod-config = <0x02>;
	oplus,ofp-need-to-wait-data-before-aod-on;
	oplus,ofp-aod-off-frame-cost = <1>;
	/* adfr config */
	oplus,adfr-config = <0xe51>;  // 0b0000'0000'0101'0001
	oplus,adfr-test-te-gpio = <&tlmm 85 0>;
	/* just for qsync enable*/
	qcom,qsync-enable;
	qcom,mdss-dsi-qsync-min-refresh-rate = <30>;

	// qcom,dsi-dyn-clk-enable;

	qcom,mdss-dsi-display-timings {
		timing@sdc_fhd_120 { /* FHD+ 120hz 1094.4Mbps */
			qcom,mdss-dsi-panel-phy-timings = [00 21 09 09 19 17 09 09 09 02 04 00 1C 0E];
			qcom,display-topology = <1 1 1>,<2 2 1>;
			qcom,default-topology-index = <1>;
			//qcom,partial-update-enabled = "single_roi";
			//qcom,panel-roi-alignment = <1264 60 1264 60 1264 60>;
			qcom,dsi-mode-te-width-us = <315>;
		};
	};
};

&dsi_panel_AC180_P_3_A0020_dsc_cmd {
	qcom,mdss-dsi-display-timings {
		timing@sdc_fhd_120 { /* FHD+ 120hz 1094.4Mbps */
			/* standard adfr */
			qcom,disable-rsc-solver;
			qcom,mdss-dsi-h-sync-skew = <0>;
			oplus,adfr-min-fps-mapping-table = <120 60 30 20 10 1>;
			oplus,adfr-idle-off-min-fps = <20>;
			oplus,adfr-high-precision-fps-mapping-table = <120 90 72 60>;

			qcom,mdss-dsi-adfr-min-fps-0-command = [
				39 00 00 40 00 00 04 FF 5A A5 2D
				39 00 00 40 00 00 03 83 00 00
				39 00 00 00 00 00 04 FF 5A A5 00
			];
			qcom,mdss-dsi-adfr-min-fps-1-command = [
				39 00 00 40 00 00 04 FF 5A A5 2D
				39 00 00 40 00 00 03 83 01 00
				39 00 00 00 00 00 04 FF 5A A5 00
			];
			qcom,mdss-dsi-adfr-min-fps-2-command = [
				39 00 00 40 00 00 04 FF 5A A5 2D
				39 00 00 40 00 00 03 83 03 00
				39 00 00 00 00 00 04 FF 5A A5 00
			];
			qcom,mdss-dsi-adfr-min-fps-3-command = [
				39 00 00 40 00 00 04 FF 5A A5 2D
				39 00 00 40 00 00 03 83 05 00
				39 00 00 00 00 00 04 FF 5A A5 00
			];
			qcom,mdss-dsi-adfr-min-fps-4-command = [
				39 00 00 40 00 00 04 FF 5A A5 2D
				39 00 00 40 00 00 03 83 0B 00
				39 00 00 00 00 00 04 FF 5A A5 00
			];
			qcom,mdss-dsi-adfr-min-fps-5-command = [
				39 00 00 40 00 00 04 FF 5A A5 2D
				39 00 00 40 00 00 03 83 77 00
				39 00 00 00 00 00 04 FF 5A A5 00
			];
			qcom,mdss-dsi-hpwm-adfr-min-fps-0-command = [
				39 00 00 40 00 00 04 FF 5A A5 2D
				39 00 00 40 00 00 03 83 00 00
				39 00 00 00 00 00 04 FF 5A A5 00
			];
			qcom,mdss-dsi-hpwm-adfr-min-fps-1-command = [
				39 00 00 40 00 00 04 FF 5A A5 2D
				39 00 00 40 00 00 03 83 01 00
				39 00 00 00 00 00 04 FF 5A A5 00
			];
			qcom,mdss-dsi-hpwm-adfr-min-fps-2-command = [
				39 00 00 40 00 00 04 FF 5A A5 2D
				39 00 00 40 00 00 03 83 03 00
				39 00 00 00 00 00 04 FF 5A A5 00
			];
			qcom,mdss-dsi-hpwm-adfr-min-fps-3-command = [
				39 00 00 40 00 00 04 FF 5A A5 2D
				39 00 00 40 00 00 03 83 05 00
				39 00 00 00 00 00 04 FF 5A A5 00
			];
			qcom,mdss-dsi-hpwm-adfr-min-fps-4-command = [
				39 00 00 40 00 00 04 FF 5A A5 2D
				39 00 00 40 00 00 03 83 0B 00
				39 00 00 00 00 00 04 FF 5A A5 00
			];
			qcom,mdss-dsi-hpwm-adfr-min-fps-5-command = [
				39 00 00 40 00 00 04 FF 5A A5 2D
				39 00 00 40 00 00 03 83 77 00
				39 00 00 00 00 00 04 FF 5A A5 00
			];
			qcom,mdss-dsi-bigdc-adfr-min-fps-0-command = [
				39 00 00 40 00 00 04 FF 5A A5 2D
				39 00 00 40 00 00 03 84 00 00
				39 00 00 00 00 00 04 FF 5A A5 00
			];
			qcom,mdss-dsi-bigdc-adfr-min-fps-1-command = [
				39 00 00 40 00 00 04 FF 5A A5 2D
				39 00 00 40 00 00 03 84 01 00
				39 00 00 00 00 00 04 FF 5A A5 00
			];
			qcom,mdss-dsi-bigdc-adfr-min-fps-2-command = [
				39 00 00 40 00 00 04 FF 5A A5 2D
				39 00 00 40 00 00 03 84 03 00
				39 00 00 00 00 00 04 FF 5A A5 00
			];
			qcom,mdss-dsi-bigdc-adfr-min-fps-3-command = [
				39 00 00 40 00 00 04 FF 5A A5 2D
				39 00 00 40 00 00 03 84 05 00
				39 00 00 00 00 00 04 FF 5A A5 00
			];
			qcom,mdss-dsi-bigdc-adfr-min-fps-4-command = [
				39 00 00 40 00 00 04 FF 5A A5 2D
				39 00 00 40 00 00 03 84 0B 00
				39 00 00 00 00 00 04 FF 5A A5 00
			];
			qcom,mdss-dsi-bigdc-adfr-min-fps-5-command = [
				39 00 00 40 00 00 04 FF 5A A5 2D
				39 00 00 40 00 00 03 84 77 00
				39 00 00 00 00 00 04 FF 5A A5 00
			];

			qcom,mdss-dsi-adfr-high-precision-fps-0-command = [
				39 00 00 40 00 00 04 FF 5A A5 2D
				39 00 00 40 00 00 02 F2 00
				39 00 00 40 00 00 04 FF 5A A5 02
				39 00 00 40 00 00 05 C0 03 00 00 00
				39 00 00 00 00 00 09 B0 00 80 00 10 00 00 00 00
				39 00 00 40 00 00 04 FF 5A A5 00
				15 00 00 00 00 00 02 60 00
			];
			qcom,mdss-dsi-adfr-high-precision-fps-1-command = [
				39 00 00 40 00 00 04 FF 5A A5 02
				39 00 00 40 00 00 05 C0 03 00 00 00
				39 00 00 00 00 00 09 B0 00 83 00 10 00 00 00 00
				39 00 00 40 00 00 04 FF 5A A5 00
				15 00 00 00 00 00 02 60 02
			];
			qcom,mdss-dsi-adfr-high-precision-fps-2-command = [
				39 00 00 40 00 00 04 FF 5A A5 02
				39 00 00 40 00 00 05 C0 03 00 00 00
				39 00 00 00 00 00 09 B0 00 83 00 10 00 00 00 00
				39 00 00 40 00 00 04 FF 5A A5 00
				15 00 00 00 00 00 02 60 04
			];
			qcom,mdss-dsi-adfr-high-precision-fps-3-command = [
				39 00 00 40 00 00 04 FF 5A A5 2D
				39 00 00 40 00 00 02 F2 01
				39 00 00 40 00 00 04 FF 5A A5 02
				39 00 00 40 00 00 05 C0 03 00 00 00
				39 00 00 00 00 00 09 B0 00 80 00 10 00 00 00 00
				39 00 00 40 00 00 04 FF 5A A5 00
				15 00 00 00 00 00 02 60 00
			];

			qcom,mdss-dsi-hpwm-adfr-high-precision-fps-0-command = [
				39 00 00 40 00 00 04 FF 5A A5 2D
				39 00 00 40 00 00 02 F2 00
				39 00 00 40 00 00 04 FF 5A A5 02
				39 00 00 40 00 00 05 C0 03 00 00 00
				39 00 00 00 00 00 09 B0 00 80 00 10 00 00 00 00
				39 00 00 40 00 00 04 FF 5A A5 00
				15 00 00 00 00 00 02 60 00
			];
			qcom,mdss-dsi-hpwm-adfr-high-precision-fps-1-command = [
				39 00 00 00 00 00 04 FF 5A A5 00
			];
			qcom,mdss-dsi-hpwm-adfr-high-precision-fps-2-command = [
				39 00 00 00 00 00 04 FF 5A A5 00
			];
			qcom,mdss-dsi-hpwm-adfr-high-precision-fps-3-command = [
				39 00 00 40 00 00 04 FF 5A A5 2D
				39 00 00 40 00 00 02 F2 01
				39 00 00 40 00 00 04 FF 5A A5 02
				39 00 00 40 00 00 05 C0 03 00 00 00
				39 00 00 00 00 00 09 B0 00 80 00 10 00 00 00 00
				39 00 00 40 00 00 04 FF 5A A5 00
				15 00 00 00 00 00 02 60 00
			];

			qcom,mdss-dsi-bigdc-adfr-high-precision-fps-0-command = [
				39 00 00 40 00 00 04 FF 5A A5 2D
				39 00 00 40 00 00 02 F2 00
				39 00 00 40 00 00 04 FF 5A A5 02
				39 00 00 40 00 00 05 C0 03 00 00 00
				39 00 00 00 00 00 09 B0 00 80 00 10 00 00 00 00
				39 00 00 40 00 00 04 FF 5A A5 00
				15 00 00 00 00 00 02 60 01
			];
			qcom,mdss-dsi-bigdc-adfr-high-precision-fps-1-command = [
				39 00 00 00 00 00 04 FF 5A A5 00
			];
			qcom,mdss-dsi-bigdc-adfr-high-precision-fps-2-command = [
				39 00 00 00 00 00 04 FF 5A A5 00
			];
			qcom,mdss-dsi-bigdc-adfr-high-precision-fps-3-command = [
				39 00 00 40 00 00 04 FF 5A A5 2D
				39 00 00 40 00 00 02 F2 01
				39 00 00 40 00 00 04 FF 5A A5 02
				39 00 00 40 00 00 05 C0 03 00 00 00
				39 00 00 00 00 00 09 B0 00 80 00 10 00 00 00 00
				39 00 00 40 00 00 04 FF 5A A5 00
				15 00 00 00 00 00 02 60 01
			];

			qcom,mdss-dsi-adfr-min-fps-0-command-state = "dsi_hs_mode";
			qcom,mdss-dsi-adfr-min-fps-1-command-state = "dsi_hs_mode";
			qcom,mdss-dsi-adfr-min-fps-2-command-state = "dsi_hs_mode";
			qcom,mdss-dsi-adfr-min-fps-3-command-state = "dsi_hs_mode";
			qcom,mdss-dsi-adfr-min-fps-4-command-state = "dsi_hs_mode";
			qcom,mdss-dsi-adfr-min-fps-5-command-state = "dsi_hs_mode";
			qcom,mdss-dsi-hpwm-adfr-min-fps-0-command-state = "dsi_hs_mode";
			qcom,mdss-dsi-hpwm-adfr-min-fps-1-command-state = "dsi_hs_mode";
			qcom,mdss-dsi-hpwm-adfr-min-fps-2-command-state = "dsi_hs_mode";
			qcom,mdss-dsi-hpwm-adfr-min-fps-3-command-state = "dsi_hs_mode";
			qcom,mdss-dsi-hpwm-adfr-min-fps-4-command-state = "dsi_hs_mode";
			qcom,mdss-dsi-hpwm-adfr-min-fps-5-command-state = "dsi_hs_mode";
			qcom,mdss-dsi-bigdc-adfr-min-fps-0-command-state = "dsi_hs_mode";
			qcom,mdss-dsi-bigdc-adfr-min-fps-1-command-state = "dsi_hs_mode";
			qcom,mdss-dsi-bigdc-adfr-min-fps-2-command-state = "dsi_hs_mode";
			qcom,mdss-dsi-bigdc-adfr-min-fps-3-command-state = "dsi_hs_mode";
			qcom,mdss-dsi-bigdc-adfr-min-fps-4-command-state = "dsi_hs_mode";
			qcom,mdss-dsi-bigdc-adfr-min-fps-5-command-state = "dsi_hs_mode";
			qcom,mdss-dsi-adfr-high-precision-fps-0-command-state = "dsi_hs_mode";
			qcom,mdss-dsi-adfr-high-precision-fps-1-command-state = "dsi_hs_mode";
			qcom,mdss-dsi-adfr-high-precision-fps-2-command-state = "dsi_hs_mode";
			qcom,mdss-dsi-adfr-high-precision-fps-3-command-state = "dsi_hs_mode";
			qcom,mdss-dsi-hpwm-adfr-high-precision-fps-0-command-state = "dsi_hs_mode";
			qcom,mdss-dsi-hpwm-adfr-high-precision-fps-1-command-state = "dsi_hs_mode";
			qcom,mdss-dsi-hpwm-adfr-high-precision-fps-2-command-state = "dsi_hs_mode";
			qcom,mdss-dsi-hpwm-adfr-high-precision-fps-3-command-state = "dsi_hs_mode";
			qcom,mdss-dsi-bigdc-adfr-high-precision-fps-0-command-state = "dsi_hs_mode";
			qcom,mdss-dsi-bigdc-adfr-high-precision-fps-1-command-state = "dsi_hs_mode";
			qcom,mdss-dsi-bigdc-adfr-high-precision-fps-2-command-state = "dsi_hs_mode";
			qcom,mdss-dsi-bigdc-adfr-high-precision-fps-3-command-state = "dsi_hs_mode";
		};
	};
};

&dsi_panel_AC180_P_3_A0020_dsc_cmd {
	qcom,panel_voltage_vddi_name = "vddio";
	qcom,panel_voltage_vddi = <0 1800000 1850000 1950000>;
	qcom,panel_voltage_vddr_name = "vddio";
	qcom,panel_voltage_vddr = <1 1800000 1850000 1950000>;
};

&dsi_panel_AC180_P_3_A0020_dsc_cmd{
	/* demura dbv config */

	/* pwm config */
	/*	oplus,pwm-switch-config:
		Bit0: pwm feature enable
		Bit1: pwm mode switch enable, need to config switch cmds
		Bit2: force enabled pwm mode switch cmd, will send mode cmd even dbv threshold cmd feature is configed
		Bit3: pwm dbv threshold pulse switch enable, need to config threshold switch cmds
		Bit4: wait te before sending pwm dbv threshold pulse switch cmd
		Bit5: replace specific cmd to other cmd while in pwm 1pulse mode
		Bit6: sending extend cmd while panel power on accroding to current pwm mode
		Bit7: sending extend cmd while timing switch accroding to current pwm pulse level
		Bit8: sending extend cmd after sending dbv threshold cmd in another thread
		...
		Bit24:support pwm mode0
		Bit25:support pwm mode1
		Bit25:support pwm mode2
	*/
	oplus,pwm-switch-config = <0x0700007F>;
	/*	oplus,pwm-switch-mode0-states-info/oplus,pwm-switch-mode1-states-info:
		Specific dbv threshold and pulse info of 2 pwm mode, for pulse, 0 symbols 1pulse,
		1symbols 3pulse and 2 symbols 18pulse. The format should be 1 dbv threshold info with
		2 pwm pulse levels left and right(for example, <2 1087 1> means 18pulse while dbv <= 1087
		and 3pulse while dbv > 1087), or only one pulse level, no threshold.
	*/
	oplus,pwm-switch-mode0-states-info = <2 1162 1>;
	oplus,pwm-switch-mode1-states-info = <2 1162 0>;
	oplus,pwm-switch-mode2-states-info = <0>;
	/*	oplus,pwm-cmd-switch-map:
		Specific cmd replace relationship while in switch on(1pulse) mode. It is a string array that
		compose with cmd names, every 2 names combine 1 map. For example, map "'a', 'b'" means replace
		a to b while sending a in switch on mode.
	*/
	oplus,pwm-cmd-switch-map = "qcom,mdss-dsi-nolp-command", "qcom,mdss-dsi-aod-off-pwm-mode2-command",
			"qcom,mdss-dsi-timing-switch-command", "qcom,mdss-dsi-timming-switch-pwm-mode2-command";

	oplus,pwm-compatible-mode;
	oplus,cmdq-sync-support;
	oplus,change-voltage-before-panel-bl-0-enable;
	oplus,interval-time-nolp-pre;

	//oplus,gamma-compensation-support;
};
